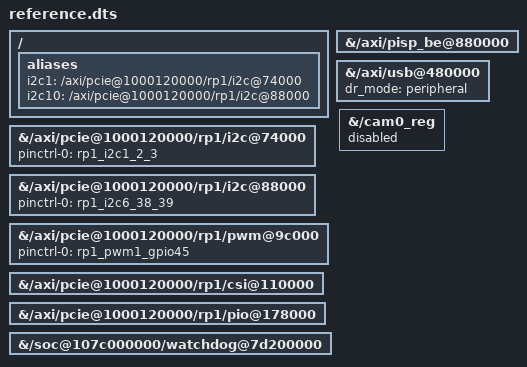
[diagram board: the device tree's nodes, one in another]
// Generated by `lemnos-ctl tree` from board "reference". Do not edit: change the
// board file or the SoC map, and generate again.
// Every fragment says why it is here. Node paths are the base tree's.
/dts-v1/;
/plugin/;
/ {
	// i2c: an I2C bus on RP1 (designware); the board's i2c-1 (alias i2c1, the name "i2c-1") on GPIO2, GPIO3
	fragment@0 {
		target-path = "/axi/pcie@1000120000/rp1/i2c@74000";
		__overlay__ {
			status = "okay";
			pinctrl-names = "default";
			pinctrl-0 = <&rp1_i2c1_2_3>;
		};
	};
	// the runtime name comes out of alias i2c1
	fragment@1 {
		target-path = "/";
		__overlay__ {
			aliases { i2c1 = "/axi/pcie@1000120000/rp1/i2c@74000"; };
		};
	};
	// i2c: an I2C bus on RP1 (designware): the camera and display connector's bus, the board's i2c-10 (alias i2c10, the name "i2c-10") on GPIO38, GPIO39
	fragment@2 {
		target-path = "/axi/pcie@1000120000/rp1/i2c@88000";
		__overlay__ {
			status = "okay";
			pinctrl-names = "default";
			pinctrl-0 = <&rp1_i2c6_38_39>;
		};
	};
	// the runtime name comes out of alias i2c10
	fragment@3 {
		target-path = "/";
		__overlay__ {
			aliases { i2c10 = "/axi/pcie@1000120000/rp1/i2c@88000"; };
		};
	};
	// pwm: a PWM channel on RP1; the fan's pulse output (a `pwm:NODE:CHANNEL` name's NODE is this path) on GPIO45
	fragment@4 {
		target-path = "/axi/pcie@1000120000/rp1/pwm@9c000";
		__overlay__ {
			status = "okay";
			pinctrl-names = "default";
			pinctrl-0 = <&rp1_pwm1_gpio45>;
		};
	};
	// csi: the camera receiver; the module drives it, and the stock receiver driver must not bind
	fragment@5 {
		target-path = "/axi/pcie@1000120000/rp1/csi@110000";
		__overlay__ {
			status = "okay";
		};
	};
	// block: the PiSP back end, the ISP's processing block; the module drives it
	fragment@6 {
		target-path = "/axi/pisp_be@880000";
		__overlay__ {
			status = "okay";
		};
	};
	// pio: the RP1 PIO block, which the module's state machines and the PIO I2C bus run on
	fragment@7 {
		target-path = "/axi/pcie@1000120000/rp1/pio@178000";
		__overlay__ {
			status = "okay";
		};
	};
	// usb-peripheral: the SoC's USB controller in peripheral mode, for a USB gadget
	fragment@8 {
		target-path = "/axi/usb@480000";
		__overlay__ {
			status = "okay";
			dr_mode = "peripheral";
		};
	};
	// watchdog: the hardware watchdog, on for a managed board
	fragment@9 {
		target-path = "/soc@107c000000/watchdog@7d200000";
		__overlay__ {
			status = "okay";
		};
	};
	// disabled: base "module-io" /cam0_reg: the camera power regulator's enable pin (RP1 GPIO34); a Lemnos power switch drives it; the board gives gpio:pinctrl-rp1:34 to Lemnos
	fragment@10 {
		target-path = "/cam0_reg";
		__overlay__ {
			status = "disabled";
		};
	};
};
